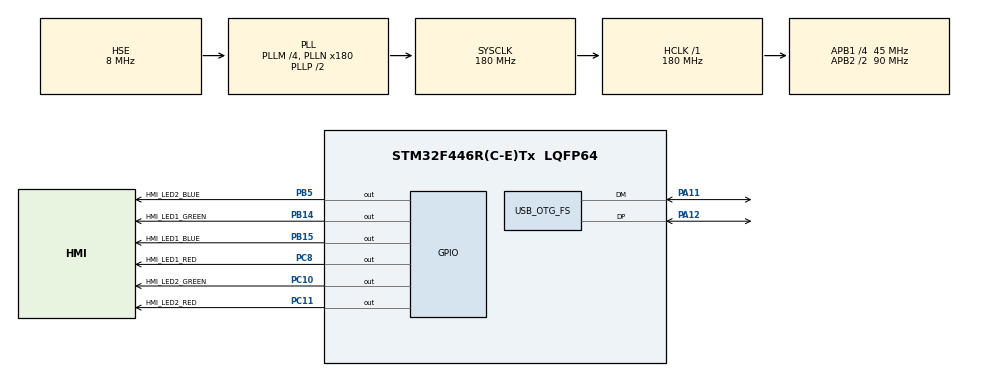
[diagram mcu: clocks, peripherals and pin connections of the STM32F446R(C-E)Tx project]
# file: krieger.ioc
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Mcu.Family=STM32F4
Mcu.Name=STM32F446R(C-E)Tx
Mcu.Package=LQFP64
NVIC.OTG_FS_IRQn=true\:0\:0\:false\:false\:true\:false\:true
NVIC.PriorityGroup=NVIC_PRIORITYGROUP_4
PA11.Mode=Device_Only
PA11.Signal=USB_OTG_FS_DM
PA12.Mode=Device_Only
PA12.Signal=USB_OTG_FS_DP
PA13.Mode=Serial_Wire
PA13.Signal=SYS_JTMS-SWDIO
PA14.Mode=Serial_Wire
PA14.Signal=SYS_JTCK-SWCLK
PB14.GPIO_Label=HMI_LED1_GREEN
PB14.Signal=GPIO_Output
PB15.GPIO_Label=HMI_LED1_BLUE
PB15.Signal=GPIO_Output
PB5.GPIO_Label=HMI_LED2_BLUE
PB5.Signal=GPIO_Output
PC10.GPIO_Label=HMI_LED2_GREEN
PC10.Signal=GPIO_Output
PC11.GPIO_Label=HMI_LED2_RED
PC11.Signal=GPIO_Output
PC8.GPIO_Label=HMI_LED1_RED
PC8.Signal=GPIO_Output
PH0-OSC_IN.Mode=HSE-External-Oscillator
PH0-OSC_IN.Signal=RCC_OSC_IN
PH1-OSC_OUT.Mode=HSE-External-Oscillator
PH1-OSC_OUT.Signal=RCC_OSC_OUT
ProjectManager.HeapSize=0x200
ProjectManager.StackSize=0x400
ProjectManager.TargetToolchain=STM32CubeIDE
RCC.AHBFreq_Value=180000000
RCC.APB1CLKDivider=RCC_HCLK_DIV4
RCC.APB1Freq_Value=45000000
RCC.APB1TimFreq_Value=90000000
RCC.APB2CLKDivider=RCC_HCLK_DIV2
RCC.APB2Freq_Value=90000000
RCC.APB2TimFreq_Value=180000000
RCC.CortexFreq_Value=180000000
RCC.HCLKFreq_Value=180000000
RCC.HSE_VALUE=8000000
RCC.PLLM=4
RCC.PLLN=180
RCC.PLLQ=7
RCC.PLLSAIM=4
RCC.PLLSAIN=96
RCC.PLLSAIP=RCC_PLLSAIP_DIV4
RCC.PLLSourceVirtual=RCC_PLLSOURCE_HSE
RCC.SYSCLKFreq_VALUE=180000000
RCC.SYSCLKSource=RCC_SYSCLKSOURCE_PLLCLK
RCC.USBCLockSelection=RCC_CLK48CLKSOURCE_PLLSAIP
RCC.USBFreq_Value=48000000
RCC.VCOOutputFreq_Value=360000000
USB_DEVICE.CLASS_NAME_FS=CDC
USB_DEVICE.USBD_DEBUG_LEVEL-CDC_FS=3
USB_DEVICE.VirtualMode-CDC_FS=Cdc
USB_DEVICE.VirtualModeFS=Cdc_FS
USB_OTG_FS.VirtualMode=Device_Only
VP_USB_DEVICE_VS_USB_DEVICE_CDC_FS.Mode=CDC_FS
board=custom

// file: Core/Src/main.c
/* USER CODE BEGIN Header */
/**
  ******************************************************************************
  * @file           : main.c
  * @brief          : Main program body
  ******************************************************************************
  * @attention
  *
  * <h2><center>&copy; Copyright (c) 2021 STMicroelectronics.
  * All rights reserved.</center></h2>
  *
  * This software component is licensed by ST under BSD 3-Clause license,
  * the "License"; You may not use this file except in compliance with the
  * License. You may obtain a copy of the License at:
  *                        opensource.org/licenses/BSD-3-Clause
  *
  ******************************************************************************
  */
/* USER CODE END Header */
#include "main.h"
#include "usb_device.h"

/* USER CODE BEGIN Includes */
#include "usbd_cdc_if.h"

/* USER CODE END Includes */

void SystemClock_Config(void);
static void MX_GPIO_Init(void);

int main(void)
{

  /* MCU Configuration--------------------------------------------------------*/

  /* Reset of all peripherals, Initializes the Flash interface and the Systick. */
  HAL_Init();

  /* Configure the system clock */
  SystemClock_Config();

  /* Initialize all configured peripherals */
  MX_GPIO_Init();
  MX_USB_DEVICE_Init();

  /* Infinite loop */
  while (1)
  {

    /* USER CODE BEGIN 3 */
    HAL_GPIO_WritePin(HMI_LED1_GREEN_GPIO_Port, HMI_LED1_GREEN_Pin, GPIO_PIN_SET);
    HAL_Delay(100);
    HAL_GPIO_WritePin(HMI_LED1_GREEN_GPIO_Port, HMI_LED1_GREEN_Pin, GPIO_PIN_RESET);
    HAL_Delay(900);

    CDC_Transmit_FS( (uint8_t*)"0123456789\n", 11 );
  }
  /* USER CODE END 3 */
}

void SystemClock_Config(void)
{
  RCC_OscInitTypeDef RCC_OscInitStruct = {0};
  RCC_ClkInitTypeDef RCC_ClkInitStruct = {0};
  RCC_PeriphCLKInitTypeDef PeriphClkInitStruct = {0};

  /** Configure the main internal regulator output voltage
  */
  __HAL_RCC_PWR_CLK_ENABLE();
  __HAL_PWR_VOLTAGESCALING_CONFIG(PWR_REGULATOR_VOLTAGE_SCALE1);
  /** Initializes the RCC Oscillators according to the specified parameters
  * in the RCC_OscInitTypeDef structure.
  */
  RCC_OscInitStruct.OscillatorType = RCC_OSCILLATORTYPE_HSE;
  RCC_OscInitStruct.HSEState = RCC_HSE_ON;
  RCC_OscInitStruct.PLL.PLLState = RCC_PLL_ON;
  RCC_OscInitStruct.PLL.PLLSource = RCC_PLLSOURCE_HSE;
  RCC_OscInitStruct.PLL.PLLM = 4;
  RCC_OscInitStruct.PLL.PLLN = 180;
  RCC_OscInitStruct.PLL.PLLP = RCC_PLLP_DIV2;
  RCC_OscInitStruct.PLL.PLLQ = 7;
  RCC_OscInitStruct.PLL.PLLR = 2;
  if (HAL_RCC_OscConfig(&RCC_OscInitStruct) != HAL_OK)
  {
    Error_Handler();
  }
  /** Activate the Over-Drive mode
  */
  if (HAL_PWREx_EnableOverDrive() != HAL_OK)
  {
    Error_Handler();
  }
  /** Initializes the CPU, AHB and APB buses clocks
  */
  RCC_ClkInitStruct.ClockType = RCC_CLOCKTYPE_HCLK|RCC_CLOCKTYPE_SYSCLK
                              |RCC_CLOCKTYPE_PCLK1|RCC_CLOCKTYPE_PCLK2;
  RCC_ClkInitStruct.SYSCLKSource = RCC_SYSCLKSOURCE_PLLCLK;
  RCC_ClkInitStruct.AHBCLKDivider = RCC_SYSCLK_DIV1;
  RCC_ClkInitStruct.APB1CLKDivider = RCC_HCLK_DIV4;
  RCC_ClkInitStruct.APB2CLKDivider = RCC_HCLK_DIV2;

  if (HAL_RCC_ClockConfig(&RCC_ClkInitStruct, FLASH_LATENCY_5) != HAL_OK)
  {
    Error_Handler();
  }
  PeriphClkInitStruct.PeriphClockSelection = RCC_PERIPHCLK_CLK48;
  PeriphClkInitStruct.PLLSAI.PLLSAIM = 4;
  PeriphClkInitStruct.PLLSAI.PLLSAIN = 96;
  PeriphClkInitStruct.PLLSAI.PLLSAIQ = 2;
  PeriphClkInitStruct.PLLSAI.PLLSAIP = RCC_PLLSAIP_DIV4;
  PeriphClkInitStruct.PLLSAIDivQ = 1;
  PeriphClkInitStruct.Clk48ClockSelection = RCC_CLK48CLKSOURCE_PLLSAIP;
  if (HAL_RCCEx_PeriphCLKConfig(&PeriphClkInitStruct) != HAL_OK)
  {
    Error_Handler();
  }
}

static void MX_GPIO_Init(void)
{
  GPIO_InitTypeDef GPIO_InitStruct = {0};

  /* GPIO Ports Clock Enable */
  __HAL_RCC_GPIOH_CLK_ENABLE();
  __HAL_RCC_GPIOB_CLK_ENABLE();
  __HAL_RCC_GPIOC_CLK_ENABLE();
  __HAL_RCC_GPIOA_CLK_ENABLE();

  /*Configure GPIO pin Output Level */
  HAL_GPIO_WritePin(GPIOB, HMI_LED1_GREEN_Pin|HMI_LED1_BLUE_Pin|HMI_LED2_BLUE_Pin, GPIO_PIN_RESET);

  /*Configure GPIO pin Output Level */
  HAL_GPIO_WritePin(GPIOC, HMI_LED1_RED_Pin|HMI_LED2_GREEN_Pin|HMI_LED2_RED_Pin, GPIO_PIN_RESET);

  /*Configure GPIO pins : HMI_LED1_GREEN_Pin HMI_LED1_BLUE_Pin HMI_LED2_BLUE_Pin */
  GPIO_InitStruct.Pin = HMI_LED1_GREEN_Pin|HMI_LED1_BLUE_Pin|HMI_LED2_BLUE_Pin;
  GPIO_InitStruct.Mode = GPIO_MODE_OUTPUT_PP;
  GPIO_InitStruct.Pull = GPIO_NOPULL;
  GPIO_InitStruct.Speed = GPIO_SPEED_FREQ_LOW;
  HAL_GPIO_Init(GPIOB, &GPIO_InitStruct);

  /*Configure GPIO pins : HMI_LED1_RED_Pin HMI_LED2_GREEN_Pin HMI_LED2_RED_Pin */
  GPIO_InitStruct.Pin = HMI_LED1_RED_Pin|HMI_LED2_GREEN_Pin|HMI_LED2_RED_Pin;
  GPIO_InitStruct.Mode = GPIO_MODE_OUTPUT_PP;
  GPIO_InitStruct.Pull = GPIO_NOPULL;
  GPIO_InitStruct.Speed = GPIO_SPEED_FREQ_LOW;
  HAL_GPIO_Init(GPIOC, &GPIO_InitStruct);

}

void Error_Handler(void)
{
  __disable_irq();
  while (1)
  {
  }
}

/************************ (C) COPYRIGHT STMicroelectronics *****END OF FILE****/
